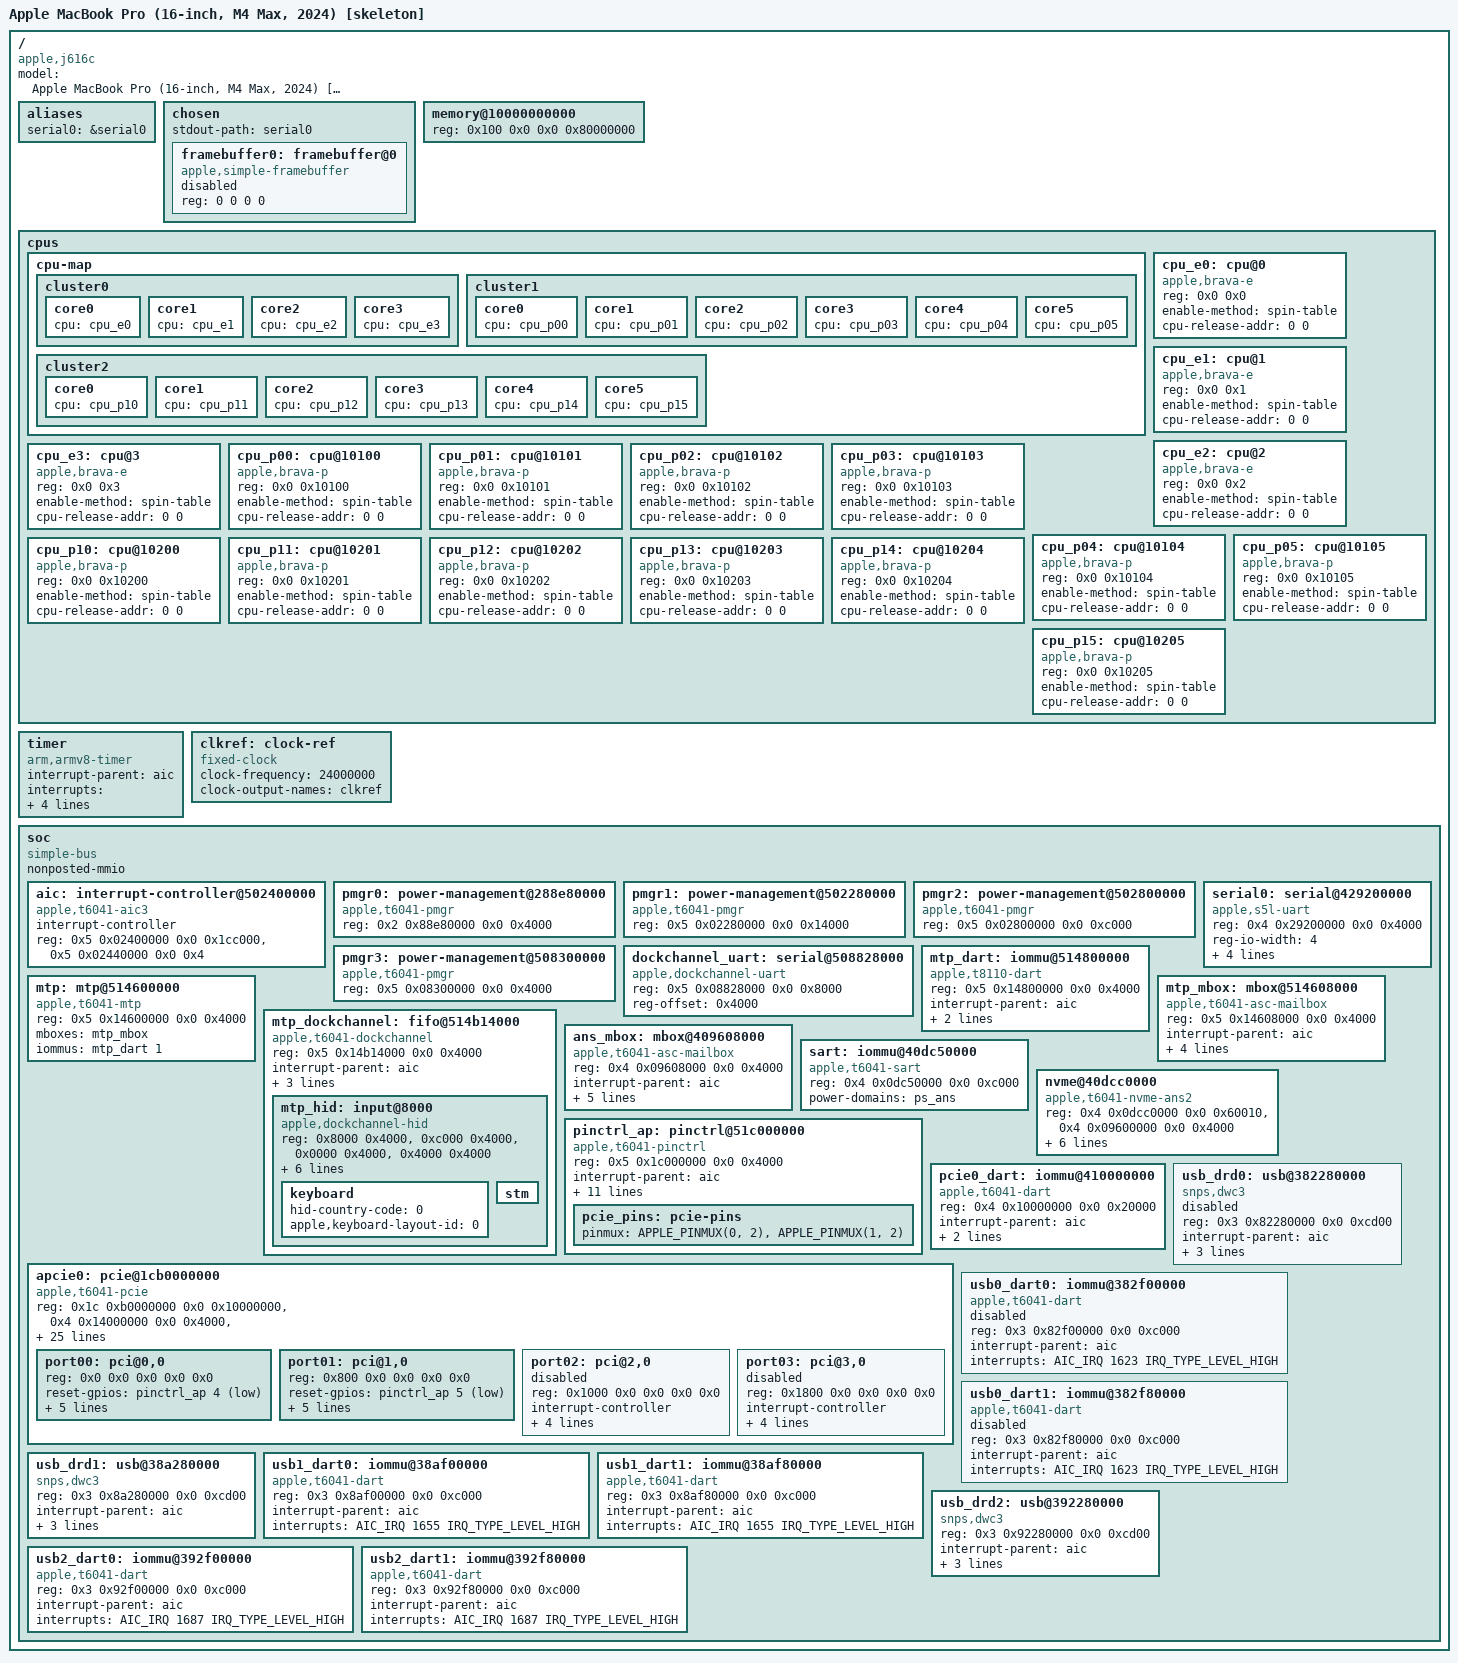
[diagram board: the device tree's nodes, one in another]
// SPDX-License-Identifier: GPL-2.0+ OR MIT
/*
 * Apple MacBook Pro (16-inch, M4 Max, 2024), J616c / T6041
 *
 * SKELETON device tree for bringing up Linux as an m1n1-HV guest far enough to
 * reach earlycon and start trapping. NOT a complete Asahi DT: peripherals
 * (DARTs, NVMe, DCP, PCIe, SMC, pmgr, pinctrl, ...) are intentionally omitted.
 *
 * Values are from on-hardware probing (see t6041_proxy_dump/):
 *   - chip-id 0x6041, board apple,j616c
 *   - CPU topology (experiments/midr.py): 4x E (cluster0) + 12x P (clusters 1,2)
 *   - AIC v3 at 0x302400000, offsets/iack confirmed against the ADT and the
 *     in-tree t8122 (M3) aic3 binding
 *   - UART base 0x429200000 (m1n1 EARLY_UART_BASE), IRQ 1559 (ADT uart0)
 *
 * TODO / unverified:
 *   - "apple,brava-{e,p}" core compatibles are placeholders (no M4 cputype yet)
 *   - /memory is a placeholder; the loader (m1n1) fixes it up
 *
 * Copyright The Asahi Linux Contributors
 */

/dts-v1/;

#include <dt-bindings/gpio/gpio.h>
#include <dt-bindings/interrupt-controller/apple-aic.h>
#include <dt-bindings/interrupt-controller/irq.h>
#include <dt-bindings/pinctrl/apple.h>

/ {
	compatible = "apple,j616c", "apple,t6041", "apple,arm-platform";
	model = "Apple MacBook Pro (16-inch, M4 Max, 2024) [skeleton]";
	#address-cells = <2>;
	#size-cells = <2>;

	aliases {
		serial0 = &serial0;
	};

	chosen {
		#address-cells = <2>;
		#size-cells = <2>;
		ranges;

		stdout-path = "serial0";

		framebuffer0: framebuffer@0 {
			compatible = "apple,simple-framebuffer", "simple-framebuffer";
			reg = <0 0 0 0>; /* filled in by m1n1 */
			status = "disabled"; /* enabled by m1n1 */
		};
	};

	memory@10000000000 {
		device_type = "memory";
		reg = <0x100 0x0 0x0 0x80000000>; /* placeholder; fixed up by loader */
	};

	cpus {
		#address-cells = <2>;
		#size-cells = <0>;

		cpu-map {
			cluster0 {
				core0 { cpu = <&cpu_e0>; };
				core1 { cpu = <&cpu_e1>; };
				core2 { cpu = <&cpu_e2>; };
				core3 { cpu = <&cpu_e3>; };
			};
			cluster1 {
				core0 { cpu = <&cpu_p00>; };
				core1 { cpu = <&cpu_p01>; };
				core2 { cpu = <&cpu_p02>; };
				core3 { cpu = <&cpu_p03>; };
				core4 { cpu = <&cpu_p04>; };
				core5 { cpu = <&cpu_p05>; };
			};
			cluster2 {
				core0 { cpu = <&cpu_p10>; };
				core1 { cpu = <&cpu_p11>; };
				core2 { cpu = <&cpu_p12>; };
				core3 { cpu = <&cpu_p13>; };
				core4 { cpu = <&cpu_p14>; };
				core5 { cpu = <&cpu_p15>; };
			};
		};

		/* E-cluster (cluster 0): MPIDR 0x800000xx */
		cpu_e0:  cpu@0     { compatible = "apple,brava-e"; device_type = "cpu"; reg = <0x0 0x0>;     enable-method = "spin-table"; cpu-release-addr = <0 0>; };
		cpu_e1:  cpu@1     { compatible = "apple,brava-e"; device_type = "cpu"; reg = <0x0 0x1>;     enable-method = "spin-table"; cpu-release-addr = <0 0>; };
		cpu_e2:  cpu@2     { compatible = "apple,brava-e"; device_type = "cpu"; reg = <0x0 0x2>;     enable-method = "spin-table"; cpu-release-addr = <0 0>; };
		cpu_e3:  cpu@3     { compatible = "apple,brava-e"; device_type = "cpu"; reg = <0x0 0x3>;     enable-method = "spin-table"; cpu-release-addr = <0 0>; };

		/* P-cluster 1: MPIDR 0x800101xx */
		cpu_p00: cpu@10100 { compatible = "apple,brava-p"; device_type = "cpu"; reg = <0x0 0x10100>; enable-method = "spin-table"; cpu-release-addr = <0 0>; };
		cpu_p01: cpu@10101 { compatible = "apple,brava-p"; device_type = "cpu"; reg = <0x0 0x10101>; enable-method = "spin-table"; cpu-release-addr = <0 0>; };
		cpu_p02: cpu@10102 { compatible = "apple,brava-p"; device_type = "cpu"; reg = <0x0 0x10102>; enable-method = "spin-table"; cpu-release-addr = <0 0>; };
		cpu_p03: cpu@10103 { compatible = "apple,brava-p"; device_type = "cpu"; reg = <0x0 0x10103>; enable-method = "spin-table"; cpu-release-addr = <0 0>; };
		cpu_p04: cpu@10104 { compatible = "apple,brava-p"; device_type = "cpu"; reg = <0x0 0x10104>; enable-method = "spin-table"; cpu-release-addr = <0 0>; };
		cpu_p05: cpu@10105 { compatible = "apple,brava-p"; device_type = "cpu"; reg = <0x0 0x10105>; enable-method = "spin-table"; cpu-release-addr = <0 0>; };

		/* P-cluster 2: MPIDR 0x800102xx */
		cpu_p10: cpu@10200 { compatible = "apple,brava-p"; device_type = "cpu"; reg = <0x0 0x10200>; enable-method = "spin-table"; cpu-release-addr = <0 0>; };
		cpu_p11: cpu@10201 { compatible = "apple,brava-p"; device_type = "cpu"; reg = <0x0 0x10201>; enable-method = "spin-table"; cpu-release-addr = <0 0>; };
		cpu_p12: cpu@10202 { compatible = "apple,brava-p"; device_type = "cpu"; reg = <0x0 0x10202>; enable-method = "spin-table"; cpu-release-addr = <0 0>; };
		cpu_p13: cpu@10203 { compatible = "apple,brava-p"; device_type = "cpu"; reg = <0x0 0x10203>; enable-method = "spin-table"; cpu-release-addr = <0 0>; };
		cpu_p14: cpu@10204 { compatible = "apple,brava-p"; device_type = "cpu"; reg = <0x0 0x10204>; enable-method = "spin-table"; cpu-release-addr = <0 0>; };
		cpu_p15: cpu@10205 { compatible = "apple,brava-p"; device_type = "cpu"; reg = <0x0 0x10205>; enable-method = "spin-table"; cpu-release-addr = <0 0>; };
	};

	timer {
		compatible = "arm,armv8-timer";
		interrupt-parent = <&aic>;
		interrupt-names = "phys", "virt", "hyp-phys", "hyp-virt";
		/* AIC v3 uses 3-cell interrupt specifiers */
		interrupts = <AIC_FIQ AIC_TMR_GUEST_PHYS IRQ_TYPE_LEVEL_HIGH>,
			     <AIC_FIQ AIC_TMR_GUEST_VIRT IRQ_TYPE_LEVEL_HIGH>,
			     <AIC_FIQ AIC_TMR_HV_PHYS IRQ_TYPE_LEVEL_HIGH>,
			     <AIC_FIQ AIC_TMR_HV_VIRT IRQ_TYPE_LEVEL_HIGH>;
	};

	clkref: clock-ref {
		compatible = "fixed-clock";
		#clock-cells = <0>;
		clock-frequency = <24000000>;
		clock-output-names = "clkref";
	};

	soc {
		compatible = "simple-bus";
		#address-cells = <2>;
		#size-cells = <2>;
		ranges;
		nonposted-mmio;

		/*
		 * AIC v3. Driver (apple,t8122-aic3) hardcodes the register
		 * offsets (INFO1=0x4, INFO3=0xc, IRQ_CFG=0x10000) which match
		 * this hardware (ADT cap0-offset=4, maxnumirq-offset=12,
		 * extint-baseaddress=0x10000), so no *-offset props are needed.
		 * event reg = core + 0x40000 (ADT aic-iack-offset).
		 */
		aic: interrupt-controller@502400000 {
			compatible = "apple,t6041-aic3", "apple,t8122-aic3";
			#interrupt-cells = <3>;
			interrupt-controller;
			/*
			 * CPU-physical address: the ADT aic reg (bus 0x302400000)
			 * is in /arm-io space, whose ranges map bus->parent with
			 * +0x200000000 (bus 0x0..0x480000000 -> 0x200000000), so
			 * the real address is 0x502400000. (Matches pmgr/cpustart
			 * at 0x5028xxxxx.) Using the raw bus 0x302400000 hits a
			 * hole and L2C ACCESS_FAULTs.
			 */
			reg = <0x5 0x02400000 0x0 0x1cc000>,
			      <0x5 0x02440000 0x0 0x4>;
			reg-names = "core", "event";
		};

		/*
		 * Power manager. Controller nodes here; the per-device
		 * power-state controllers are in t6041-pmgr.dtsi (generated
		 * from the ADT). Addresses/sizes from the ADT.
		 */
		pmgr0: power-management@288e80000 {
			compatible = "apple,t6041-pmgr", "apple,t8103-pmgr", "syscon", "simple-mfd";
			#address-cells = <1>;
			#size-cells = <1>;
			reg = <0x2 0x88e80000 0x0 0x4000>;
		};

		pmgr1: power-management@502280000 {
			compatible = "apple,t6041-pmgr", "apple,t8103-pmgr", "syscon", "simple-mfd";
			#address-cells = <1>;
			#size-cells = <1>;
			reg = <0x5 0x02280000 0x0 0x14000>;
		};

		pmgr2: power-management@502800000 {
			compatible = "apple,t6041-pmgr", "apple,t8103-pmgr", "syscon", "simple-mfd";
			#address-cells = <1>;
			#size-cells = <1>;
			reg = <0x5 0x02800000 0x0 0xc000>;
		};

		pmgr3: power-management@508300000 {
			compatible = "apple,t6041-pmgr", "apple,t8103-pmgr", "syscon", "simple-mfd";
			#address-cells = <1>;
			#size-cells = <1>;
			reg = <0x5 0x08300000 0x0 0x4000>;
		};

		serial0: serial@429200000 {
			compatible = "apple,s5l-uart";
			reg = <0x4 0x29200000 0x0 0x4000>;
			reg-io-width = <4>;
			interrupt-parent = <&aic>;
			interrupts = <AIC_IRQ 1559 IRQ_TYPE_LEVEL_HIGH>;
			clocks = <&clkref>, <&clkref>;
			clock-names = "uart", "clk_uart_baud0";
			power-domains = <&ps_uart0>;
			status = "okay";
		};

		/*
		 * DockChannel UART = the real M4 firmware/debug console (iBoot/
		 * XNU/m1n1 use it, not the s5l UART), routed out the USB-C SBU
		 * pins via VDM debug mode (read on the host with vdmtool/macvdmtool
		 * + FUSB302, picocom 115200). Pair with CONFIG_SERIAL_APPLE_DOCKCHANNEL.
		 * Data FIFO regs live at base + 0x4000, so reg-offset points the
		 * earlycon there. Base 0x508828000 = ADT /arm-io/dockchannel-uart.
		 * Use via bootarg: earlycon=dockchannel,mmio32,0x50882c000
		 */
		dockchannel_uart: serial@508828000 {
			compatible = "apple,dockchannel-uart";
			reg = <0x5 0x08828000 0x0 0x8000>;
			reg-offset = <0x4000>;
			status = "okay";
		};

		/*
		 * MTP (Multi-Touch Processor) coprocessor = the M4 internal
		 * keyboard path. OLD out-of-tree structure (apple,rtk-helper-asc4
		 * + apple,dockchannel-hid) to match THIS kernel's drivers, with the
		 * CORRECTED ASC base: the real MTP ASC is 0x514600000 (CPU_CONTROL
		 * +0x44, mailbox at +0x8000 = 0x514608000), verified live via the
		 * m1n1 proxy (StandardASC boots it; HELLO v12). Our earlier
		 * 0x514050000 was a dead all-zeros region -> the Linux -ETIME.
		 * sram reg omitted (optional; MTP uses DART-backed buffers).
		 */
		mtp_dart: iommu@514800000 {
			compatible = "apple,t8110-dart";
			reg = <0x5 0x14800000 0x0 0x4000>;
			interrupt-parent = <&aic>;
			interrupts = <AIC_IRQ 775 IRQ_TYPE_LEVEL_HIGH>;
			#iommu-cells = <1>;
			apple,dma-range = <0x100 0x0 0x1 0x0>;
		};

		mtp: mtp@514600000 {
			compatible = "apple,t6041-mtp", "apple,mtp", "apple,rtk-helper-asc4";
			reg = <0x5 0x14600000 0x0 0x4000>;
			reg-names = "asc";
			mboxes = <&mtp_mbox>;
			iommus = <&mtp_dart 1>;
			#helper-cells = <0>;
			status = "okay";
		};

		mtp_mbox: mbox@514608000 {
			compatible = "apple,t6041-asc-mailbox", "apple,asc-mailbox-v4";
			reg = <0x5 0x14608000 0x0 0x4000>;
			interrupt-parent = <&aic>;
			interrupts = <AIC_IRQ 792 IRQ_TYPE_LEVEL_HIGH>,
				     <AIC_IRQ 793 IRQ_TYPE_LEVEL_HIGH>,
				     <AIC_IRQ 794 IRQ_TYPE_LEVEL_HIGH>,
				     <AIC_IRQ 795 IRQ_TYPE_LEVEL_HIGH>;
			interrupt-names = "send-empty", "send-not-empty",
					  "recv-empty", "recv-not-empty";
			#mbox-cells = <0>;
		};

		mtp_dockchannel: fifo@514b14000 {
			compatible = "apple,t6041-dockchannel", "apple,dockchannel";
			reg = <0x5 0x14b14000 0x0 0x4000>;
			reg-names = "irq";
			interrupt-parent = <&aic>;
			interrupts = <AIC_IRQ 776 IRQ_TYPE_LEVEL_HIGH>;
			ranges = <0 0x5 0x14b28000 0x20000>;
			nonposted-mmio;
			#address-cells = <1>;
			#size-cells = <1>;
			interrupt-controller;
			#interrupt-cells = <2>;

			mtp_hid: input@8000 {
				compatible = "apple,dockchannel-hid";
				reg = <0x8000 0x4000>,
				      <0xc000 0x4000>,
				      <0x0000 0x4000>,
				      <0x4000 0x4000>;
				reg-names = "config", "data",
					    "rmt-config", "rmt-data";
				iommus = <&mtp_dart 1>;
				interrupt-parent = <&mtp_dockchannel>;
				interrupts = <2 IRQ_TYPE_LEVEL_HIGH>,
					     <3 IRQ_TYPE_LEVEL_HIGH>;
				interrupt-names = "tx", "rx";
				apple,fifo-size = <0x800>;
				apple,helper-cpu = <&mtp>;
				status = "okay";

				/* HID subdevice child nodes: the dockchannel-hid driver
				 * does of_get_child_by_name() per subdevice and ignores
				 * any without a node. The keyboard is what we want. */
				keyboard: keyboard {
					hid-country-code = <0>;
					apple,keyboard-layout-id = <0>;
				};

				/* STM must come up first: it fetches the device IDs that
				 * gate (id_ready) creation of the deferred keyboard iface. */
				stm {
				};
			};
		};

		/*
		 * NVMe (internal SSD) = the ANS RTKit coprocessor + SART + the
		 * NVMe controller. CPU-phys = ADT /arm-io/ans|sart-ans + 0x200000000
		 * (SART 0x40dc50000 confirmed live via m1n1). ANS asc 0x409600000
		 * (mailbox +0x8000), NVMe ctrl 0x40dcc0000. ANS mailbox doorbell
		 * IRQs sorted ascending (ADT lists pairs high-low); nvme IRQ = the
		 * 5th ANS interrupt (nvme-interrupt-idx=4). SART is v3 ("coastguard"
		 * = apple,t6000-sart ops). power-domains enable the NVMe controller
		 * (m1n1 L2C-faulted here because it didn't power apcie).
		 */
		ans_mbox: mbox@409608000 {
			compatible = "apple,t6041-asc-mailbox", "apple,asc-mailbox-v4";
			reg = <0x4 0x09608000 0x0 0x4000>;
			interrupt-parent = <&aic>;
			interrupts = <AIC_IRQ 1530 IRQ_TYPE_LEVEL_HIGH>,
				     <AIC_IRQ 1531 IRQ_TYPE_LEVEL_HIGH>,
				     <AIC_IRQ 1532 IRQ_TYPE_LEVEL_HIGH>,
				     <AIC_IRQ 1533 IRQ_TYPE_LEVEL_HIGH>;
			interrupt-names = "send-empty", "send-not-empty",
					  "recv-empty", "recv-not-empty";
			#mbox-cells = <0>;
			power-domains = <&ps_ans>;
		};

		sart: iommu@40dc50000 {
			compatible = "apple,t6041-sart", "apple,t6000-sart";
			reg = <0x4 0x0dc50000 0x0 0xc000>;
			power-domains = <&ps_ans>;
		};

		nvme@40dcc0000 {
			compatible = "apple,t6041-nvme-ans2", "apple,nvme-ans2";
			reg = <0x4 0x0dcc0000 0x0 0x60010>,
			      <0x4 0x09600000 0x0 0x4000>;
			reg-names = "nvme", "ans";
			interrupt-parent = <&aic>;
			interrupts = <AIC_IRQ 2583 IRQ_TYPE_LEVEL_HIGH>;
			mboxes = <&ans_mbox>;
			apple,sart = <&sart>;
			power-domains = <&ps_ans>, <&ps_apcie_st0>;
			power-domain-names = "ans", "apcie0";
			resets = <&ps_ans>;
		};

		/* ================================================================
		 * PCIe bring-up (apcie0) — internal root complex, T6041 / M4 Max.
		 *
		 * m1n1 (HV) already brings the root complex + PHY up on hardware
		 * (verified: ECAM enumerates the Apple root port). Linux's job here
		 * is: bind pcie-apple.c, drive PERST# per port (reset-gpios -> gpio0),
		 * train the links, and enumerate the internal endpoints
		 * (WLAN/BT on port0, SD-card reader on port1).
		 *
		 * All CPU-phys addresses = ADT bus addr + 0x200000000 (arm-io ranges),
		 * same convention as the AIC/pmgr/NVMe nodes above.
		 * Source: t6041_proxy_dump/adt.txt node `apcie0` / `dart-apcie0` / `gpio0`.
		 *
		 * ---- reg-names mapping (VERIFIED against pcie-apple.c) ----
		 *   pcie->base = devm_platform_ioremap_resource(pdev, 1)  -> reg[1] = "rc"
		 *       (CORE_* regs + default PHY window base + 0x84000 + 0x4000*port)
		 *   ECAM config = reg[0] = "config" (consumed by pci-host-ecam layer)
		 *   port N base = platform_get_resource_byname("portN")
		 *   port N phy  = platform_get_resource_byname("phyN")  -> t602x needs
		 *       an explicit per-port PHY-glue window (setup_refclk() pokes
		 *       PHY_LANE_CFG at port->phy). Confirmed by the M3 (t6031) template
		 *       whose phy0 = 0x...9e020000 is the per-port phy-glue region; the
		 *       ADT reg matching that on T6041 is 0x2170{20,24,28,2c}000.
		 *   ADT reg index map used below (0-based, per adt.txt apcie0.reg[]):
		 *       reg[0]=0x1cb0000000 config   reg[1]=0x214000000 rc
		 *       reg[7]=0x210028000 port0     reg[9]=0x217020000 phy0
		 *       reg[14]=0x211028000 port1    reg[16]=0x217024000 phy1
		 *       reg[21]=0x212028000 port2    reg[23]=0x217028000 phy2
		 *       reg[28]=0x213028000 port3    reg[30]=0x21702c000 phy3
		 *   (reg[2] coalesced-PHY and reg[4] axi2af are owned by m1n1; omitted.)
		 *
		 * AIC interrupts use the T6041 3-cell form <AIC_IRQ N flag> (this die
		 * has no die-index cell — cf. the M3 t6031 which uses 4 cells).
		 *
		 * ASSUMPTIONS / TO VERIFY ON FIRST BOOT (flagged):
		 *  - port config window size: ADT says 0x8000, M3 template uses 0x4000;
		 *    driver only touches < 0x3800, so 0x4000 is safe. Using 0x4000.
		 *  - PERST GPIOs: ADT apcie0 `function-perst` = GPIO(4)/GPIO(5),
		 *    active-low -> port0=gpio0 pin4, port1=gpio0 pin5.
		 *  - power-domain: ps_apcie_gp (matches t6041-pmgr.dtsi label + t8103).
		 *  - single DART (dart-apcie0) with per-function SIDs 0x10/0x11/0x12,
		 *    unlike M3's per-port DARTs. iommu-map routes each port's RID to a
		 *    distinct SID on the same DART. See DART note below.
		 * ================================================================ */

		/*
		 * AP GPIO / pin controller (gpio0). Needed so reset-gpios resolves.
		 * ADT gpio0: compatible gpio,t8101, reg 0x31C000000 (-> 0x51C000000),
		 * 200 pins, 7 int-groups (AIC IRQs 478..484). Driver binds
		 * "apple,t8103-pinctrl". power-domains omitted: t6041-pmgr.dtsi has no
		 * ps_gpio yet and m1n1/iBoot leaves the GPIO block powered.
		 */
		pinctrl_ap: pinctrl@51c000000 {
			compatible = "apple,t6041-pinctrl", "apple,t8103-pinctrl";
			reg = <0x5 0x1c000000 0x0 0x4000>;

			interrupt-parent = <&aic>;
			interrupts = <AIC_IRQ 478 IRQ_TYPE_LEVEL_HIGH>,
				     <AIC_IRQ 479 IRQ_TYPE_LEVEL_HIGH>,
				     <AIC_IRQ 480 IRQ_TYPE_LEVEL_HIGH>,
				     <AIC_IRQ 481 IRQ_TYPE_LEVEL_HIGH>,
				     <AIC_IRQ 482 IRQ_TYPE_LEVEL_HIGH>,
				     <AIC_IRQ 483 IRQ_TYPE_LEVEL_HIGH>,
				     <AIC_IRQ 484 IRQ_TYPE_LEVEL_HIGH>;

			gpio-controller;
			#gpio-cells = <2>;
			gpio-ranges = <&pinctrl_ap 0 0 200>;
			apple,npins = <200>;

			interrupt-controller;
			#interrupt-cells = <2>;

			/*
			 * PCIe CLKREQ# pins. From the ADT bridge functions:
			 * apcie0/pci-bridge0 function-clkreq = GPIO(pin 0, func 2),
			 * pci-bridge1 function-clkreq = GPIO(pin 1, func 2).
			 * These must be muxed to their peripheral function (2) or
			 * the device never gets its reference clock and the link
			 * won't train (PERST alone is not enough). Mirrors the
			 * pcie_pins group on M1/M2 (t8103.dtsi).
			 */
			pcie_pins: pcie-pins {
				pinmux = <APPLE_PINMUX(0, 2)>,
					 <APPLE_PINMUX(1, 2)>;
			};
		};

		/*
		 * PCIe DART (IOMMU). ONE DART on M4 (contrast M3 per-port DARTs).
		 * ADT dart-apcie0: compatible dart,t8110, reg 0x210000000
		 * (-> 0x410000000) size 0x20000, IRQ 1724, dart-id 1, sid-count 19.
		 * SIDs from ADT `sid`: 0x10 wlan, 0x11 bt, 0x12 piodma.
		 * #iommu-cells=1 (verified apple-dart of_xlate: single SID arg).
		 */
		pcie0_dart: iommu@410000000 {
			compatible = "apple,t6041-dart", "apple,t8110-dart";
			reg = <0x4 0x10000000 0x0 0x20000>;
			#iommu-cells = <1>;
			interrupt-parent = <&aic>;
			interrupts = <AIC_IRQ 1724 IRQ_TYPE_LEVEL_HIGH>;
			power-domains = <&ps_apcie_gp>;
		};

		apcie0: pcie@1cb0000000 {
			compatible = "apple,t6041-pcie", "apple,t6040-pcie";
			device_type = "pci";

			reg = <0x1c 0xb0000000 0x0 0x10000000>,	/* config / ECAM */
			      <0x4 0x14000000 0x0 0x4000>,	/* rc (pcie->base) */
			      <0x4 0x10028000 0x0 0x4000>,	/* port0 */
			      <0x4 0x11028000 0x0 0x4000>,	/* port1 */
			      <0x4 0x12028000 0x0 0x4000>,	/* port2 */
			      <0x4 0x13028000 0x0 0x4000>,	/* port3 */
			      <0x4 0x17020000 0x0 0x4000>,	/* phy0 */
			      <0x4 0x17024000 0x0 0x4000>,	/* phy1 */
			      <0x4 0x17028000 0x0 0x4000>,	/* phy2 */
			      <0x4 0x1702c000 0x0 0x4000>;	/* phy3 */
			reg-names = "config", "rc",
				    "port0", "port1", "port2", "port3",
				    "phy0", "phy1", "phy2", "phy3";

			interrupt-parent = <&aic>;
			interrupts = <AIC_IRQ 1723 IRQ_TYPE_LEVEL_HIGH>,
				     <AIC_IRQ 1732 IRQ_TYPE_LEVEL_HIGH>,
				     <AIC_IRQ 1741 IRQ_TYPE_LEVEL_HIGH>,
				     <AIC_IRQ 1750 IRQ_TYPE_LEVEL_HIGH>;

			msi-controller;
			msi-parent = <&apcie0>;
			/* msi-vector-offset=2071, #msi-vectors=32 (ADT). */
			msi-ranges = <&aic AIC_IRQ 2071 IRQ_TYPE_EDGE_RISING 32>;

			/*
			 * Single DART: route each root-port RID range to a distinct
			 * SID. RID base = (bus << 8); iommu-map-mask 0xff00 selects the
			 * bus. port0(bus1)->SID 0x10 (wlan), port1(bus2)->SID 0x11 (bt/SD).
			 * NOTE: WLAN+BT are two functions behind port0 and the ADT lists
			 * separate wlan/bt SIDs; a single SID per port may be too coarse
			 * for BT if it presents as a distinct RID. VERIFY on first boot —
			 * may need per-function iommu-map entries or a wider length.
			 */
			iommu-map = <0x100 &pcie0_dart 0x10 1>,
				    <0x200 &pcie0_dart 0x11 1>,
				    <0x300 &pcie0_dart 0x12 1>,
				    <0x400 &pcie0_dart 0x13 1>;
			iommu-map-mask = <0xff00>;

			bus-range = <0 4>;
			#address-cells = <3>;
			#size-cells = <2>;
			/*
			 * ranges (from ADT): mem64 prefetch @ 0xBC0000000 size 0x20000000,
			 * mem32 @ 0xB80000000 size 0x40000000.
			 */
			ranges = <0x43000000 0xb 0xc0000000 0xb 0xc0000000 0x0 0x20000000>,
				 <0x02000000 0x0 0xb8000000 0xb 0x80000000 0x0 0x40000000>;

			power-domains = <&ps_apcie_gp>;
			pinctrl-0 = <&pcie_pins>;
			pinctrl-names = "default";

			dma-coherent;

			status = "okay";

			/* port0: WLAN/BT. PERST# = gpio0 pin 4 (active-low). */
			port00: pci@0,0 {
				device_type = "pci";
				reg = <0x0 0x0 0x0 0x0 0x0>;
				reset-gpios = <&pinctrl_ap 4 GPIO_ACTIVE_LOW>;

				#address-cells = <3>;
				#size-cells = <2>;
				ranges;

				interrupt-controller;
				#interrupt-cells = <1>;

				interrupt-map-mask = <0 0 0 7>;
				interrupt-map = <0 0 0 1 &port00 0 0 0 0>,
						<0 0 0 2 &port00 0 0 0 1>,
						<0 0 0 3 &port00 0 0 0 2>,
						<0 0 0 4 &port00 0 0 0 3>;
				status = "okay";
			};

			/* port1: SD-card reader. PERST# = gpio0 pin 5 (active-low). */
			port01: pci@1,0 {
				device_type = "pci";
				reg = <0x800 0x0 0x0 0x0 0x0>;
				reset-gpios = <&pinctrl_ap 5 GPIO_ACTIVE_LOW>;

				#address-cells = <3>;
				#size-cells = <2>;
				ranges;

				interrupt-controller;
				#interrupt-cells = <1>;

				interrupt-map-mask = <0 0 0 7>;
				interrupt-map = <0 0 0 1 &port01 0 0 0 0>,
						<0 0 0 2 &port01 0 0 0 1>,
						<0 0 0 3 &port01 0 0 0 2>,
						<0 0 0 4 &port01 0 0 0 3>;
				status = "okay";
			};

			/* port2/port3: unused on this board; left disabled.
			 * PERST pins unknown (ADT only lists perst for port0/1). */
			port02: pci@2,0 {
				device_type = "pci";
				reg = <0x1000 0x0 0x0 0x0 0x0>;

				#address-cells = <3>;
				#size-cells = <2>;
				ranges;

				interrupt-controller;
				#interrupt-cells = <1>;

				interrupt-map-mask = <0 0 0 7>;
				interrupt-map = <0 0 0 1 &port02 0 0 0 0>,
						<0 0 0 2 &port02 0 0 0 1>,
						<0 0 0 3 &port02 0 0 0 2>,
						<0 0 0 4 &port02 0 0 0 3>;
				status = "disabled";
			};

			port03: pci@3,0 {
				device_type = "pci";
				reg = <0x1800 0x0 0x0 0x0 0x0>;

				#address-cells = <3>;
				#size-cells = <2>;
				ranges;

				interrupt-controller;
				#interrupt-cells = <1>;

				interrupt-map-mask = <0 0 0 7>;
				interrupt-map = <0 0 0 1 &port03 0 0 0 0>,
						<0 0 0 2 &port03 0 0 0 1>,
						<0 0 0 3 &port03 0 0 0 2>,
						<0 0 0 4 &port03 0 0 0 3>;
				status = "disabled";
			};
		};

		/* ================================================================
		 * USB (bring-up, USB2/HS host only) — usb-drd0..2, T6041 / M4 Max.
		 *
		 * Strategy: NO atc-phy driver exists for atc-phy,t6040 and NO
		 * sn201202x (SPMI PD) driver exists, so the full dwc3-apple +
		 * apple,t8103-atcphy + role-switch stack cannot work here yet.
		 * Instead we rely on the state m1n1 leaves behind (usb_phy_bringup
		 * runs on all ports on M3/M4: ATC powered, USB2 PHY running,
		 * pipehandler muxed to the dummy USB3 pipe, dwc3 out of reset) and
		 * bind the PLAIN dwc3 core ("snps,dwc3", no glue) in dr_mode="host".
		 * The USB2 PHY is flipped from device to host mode pre-boot via the
		 * m1n1 proxy (USB2PHY_SIG.HOST = bits 14:12 at usb2phy+0x08, with a
		 * power-down/up cycle around it, mirroring atc.c) — see
		 * t6041-usb/usb_host_prep.py. USB3/SS needs the real ATC PHY port
		 * and PD driver work; HS is enough for a root hub + devices.
		 *
		 * usb-drd0 (USB-C port 1, left-rear) is the m1n1 proxy/console port
		 * under the HV — the guest must NOT touch it, so it stays disabled.
		 *
		 * CPU-phys = ADT /arm-io/usb-drdN|dart-usbN reg + 0x200000000.
		 * dwc3 core window = ADT reg[0], size 0xcd00 like t8103.dtsi (the
		 * 0xcd00..0xcdff Apple CIO regs are left alone; those tunables only
		 * matter for USB3). dwc3 IRQ = first ADT interrupt (t8103 pattern).
		 * Each dart-usbN ADT node is TWO t8110 DART instances (+0x0 and
		 * +0x80000); dwc3 DMA is mapped through both, SID 0 on the first,
		 * SID 1 on the second, mirroring t8103.dtsi.
		 * power-domains omitted everywhere: m1n1 already enabled
		 * ATC/DART/DRD domains (usb_phy_bringup) and keeps them on; the
		 * minimal t6041-pmgr.dtsi has no ps_atc* nodes yet.
		 * ================================================================ */

		/* usb-drd0: PROXY/CONSOLE PORT (USB-C port 1) — hands off. */
		usb_drd0: usb@382280000 {
			compatible = "snps,dwc3";
			reg = <0x3 0x82280000 0x0 0xcd00>;
			interrupt-parent = <&aic>;
			interrupts = <AIC_IRQ 1619 IRQ_TYPE_LEVEL_HIGH>;
			dr_mode = "host";
			iommus = <&usb0_dart0 0>, <&usb0_dart1 1>;
			status = "disabled";
		};

		usb0_dart0: iommu@382f00000 {
			compatible = "apple,t6041-dart", "apple,t8110-dart";
			reg = <0x3 0x82f00000 0x0 0xc000>;
			#iommu-cells = <1>;
			interrupt-parent = <&aic>;
			interrupts = <AIC_IRQ 1623 IRQ_TYPE_LEVEL_HIGH>;
			status = "disabled";
		};

		usb0_dart1: iommu@382f80000 {
			compatible = "apple,t6041-dart", "apple,t8110-dart";
			reg = <0x3 0x82f80000 0x0 0xc000>;
			#iommu-cells = <1>;
			interrupt-parent = <&aic>;
			interrupts = <AIC_IRQ 1623 IRQ_TYPE_LEVEL_HIGH>;
			status = "disabled";
		};

		/* usb-drd1: USB-C port 2 (left-front). */
		usb_drd1: usb@38a280000 {
			compatible = "snps,dwc3";
			reg = <0x3 0x8a280000 0x0 0xcd00>;
			interrupt-parent = <&aic>;
			interrupts = <AIC_IRQ 1651 IRQ_TYPE_LEVEL_HIGH>;
			dr_mode = "host";
			iommus = <&usb1_dart0 0>, <&usb1_dart1 1>;
		};

		usb1_dart0: iommu@38af00000 {
			compatible = "apple,t6041-dart", "apple,t8110-dart";
			reg = <0x3 0x8af00000 0x0 0xc000>;
			#iommu-cells = <1>;
			interrupt-parent = <&aic>;
			interrupts = <AIC_IRQ 1655 IRQ_TYPE_LEVEL_HIGH>;
		};

		usb1_dart1: iommu@38af80000 {
			compatible = "apple,t6041-dart", "apple,t8110-dart";
			reg = <0x3 0x8af80000 0x0 0xc000>;
			#iommu-cells = <1>;
			interrupt-parent = <&aic>;
			interrupts = <AIC_IRQ 1655 IRQ_TYPE_LEVEL_HIGH>;
		};

		/* usb-drd2: USB-C port 3 (right). */
		usb_drd2: usb@392280000 {
			compatible = "snps,dwc3";
			reg = <0x3 0x92280000 0x0 0xcd00>;
			interrupt-parent = <&aic>;
			interrupts = <AIC_IRQ 1683 IRQ_TYPE_LEVEL_HIGH>;
			dr_mode = "host";
			iommus = <&usb2_dart0 0>, <&usb2_dart1 1>;
		};

		usb2_dart0: iommu@392f00000 {
			compatible = "apple,t6041-dart", "apple,t8110-dart";
			reg = <0x3 0x92f00000 0x0 0xc000>;
			#iommu-cells = <1>;
			interrupt-parent = <&aic>;
			interrupts = <AIC_IRQ 1687 IRQ_TYPE_LEVEL_HIGH>;
		};

		usb2_dart1: iommu@392f80000 {
			compatible = "apple,t6041-dart", "apple,t8110-dart";
			reg = <0x3 0x92f80000 0x0 0xc000>;
			#iommu-cells = <1>;
			interrupt-parent = <&aic>;
			interrupts = <AIC_IRQ 1687 IRQ_TYPE_LEVEL_HIGH>;
		};
	};
};

#include "t6041-pmgr.dtsi"
